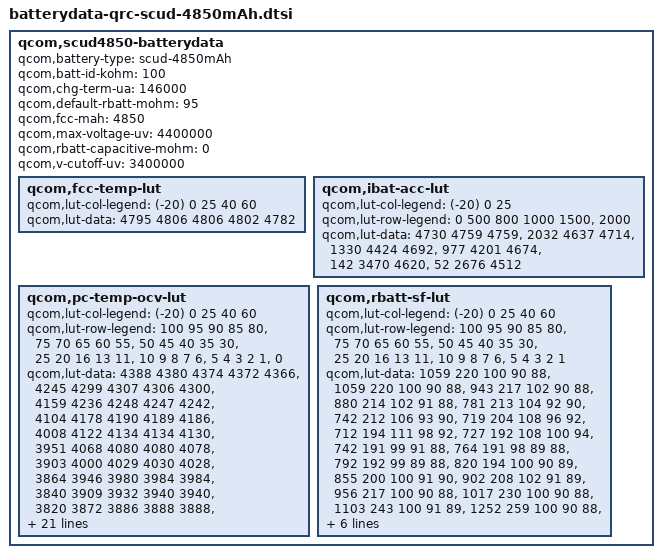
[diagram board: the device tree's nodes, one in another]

qcom,scud4850-batterydata {
	qcom,battery-type = "scud-4850mAh";
	qcom,batt-id-kohm = <100>;
	qcom,chg-term-ua = <146000>;
	qcom,default-rbatt-mohm = <95>;
	qcom,fcc-mah = <4850>;
	qcom,max-voltage-uv = <4400000>;
	qcom,rbatt-capacitive-mohm = <0>;
	qcom,v-cutoff-uv = <3400000>;

	qcom,fcc-temp-lut {
		qcom,lut-col-legend = <(-20) 0 25 40 60>;
		qcom,lut-data = <4795 4806 4806 4802 4782>;
	};

	qcom,ibat-acc-lut {
		qcom,lut-col-legend = <(-20) 0 25>;
		qcom,lut-row-legend = <0 500 800 1000 1500>,
					<2000>;
		qcom,lut-data = <4730 4759 4759>,
				<2032 4637 4714>,
				<1330 4424 4692>,
				<977 4201 4674>,
				<142 3470 4620>,
				<52 2676 4512>;
	};

	qcom,pc-temp-ocv-lut {
		qcom,lut-col-legend = <(-20) 0 25 40 60>;
		qcom,lut-row-legend = <100 95 90 85 80>,
					<75 70 65 60 55>,
					<50 45 40 35 30>,
					<25 20 16 13 11>,
					<10 9 8 7 6>,
					<5 4 3 2 1>,
					<0>;
		qcom,lut-data = <4388 4380 4374 4372 4366>,
				<4245 4299 4307 4306 4300>,
				<4159 4236 4248 4247 4242>,
				<4104 4178 4190 4189 4186>,
				<4008 4122 4134 4134 4130>,
				<3951 4068 4080 4080 4078>,
				<3903 4000 4029 4030 4028>,
				<3864 3946 3980 3984 3984>,
				<3840 3909 3932 3940 3940>,
				<3820 3872 3886 3888 3888>,
				<3802 3842 3852 3854 3853>,
				<3786 3815 3826 3828 3827>,
				<3771 3794 3806 3807 3806>,
				<3756 3778 3788 3788 3788>,
				<3740 3766 3772 3771 3768>,
				<3724 3752 3756 3750 3740>,
				<3704 3736 3738 3731 3718>,
				<3684 3716 3720 3712 3699>,
				<3665 3701 3702 3694 3682>,
				<3650 3692 3691 3685 3672>,
				<3641 3688 3687 3681 3670>,
				<3632 3684 3685 3679 3668>,
				<3620 3680 3683 3677 3666>,
				<3606 3674 3680 3674 3662>,
				<3588 3663 3674 3668 3656>,
				<3566 3646 3661 3654 3640>,
				<3538 3616 3628 3620 3604>,
				<3500 3569 3578 3568 3554>,
				<3448 3503 3508 3499 3486>,
				<3366 3404 3405 3397 3386>,
				<3200 3200 3200 3200 3200>;
	};

	qcom,rbatt-sf-lut {
		qcom,lut-col-legend = <(-20) 0 25 40 60>;
		qcom,lut-row-legend = <100 95 90 85 80>,
					<75 70 65 60 55>,
					<50 45 40 35 30>,
					<25 20 16 13 11>,
					<10 9 8 7 6>,
					<5 4 3 2 1>;
		qcom,lut-data = <1059 220 100 90 88>,
				<1059 220 100 90 88>,
				<943 217 102 90 88>,
				<880 214 102 91 88>,
				<781 213 104 92 90>,
				<742 212 106 93 90>,
				<719 204 108 96 92>,
				<712 194 111 98 92>,
				<727 192 108 100 94>,
				<742 191 99 91 88>,
				<764 191 98 89 88>,
				<792 192 99 89 88>,
				<820 194 100 90 89>,
				<855 200 100 91 90>,
				<902 208 102 91 89>,
				<956 217 100 90 88>,
				<1017 230 100 90 88>,
				<1103 243 100 91 89>,
				<1252 259 100 90 88>,
				<1396 275 100 91 88>,
				<1475 284 100 91 89>,
				<1534 291 101 92 90>,
				<1673 306 104 93 92>,
				<1865 324 106 95 94>,
				<2112 349 109 98 97>,
				<2431 379 109 98 94>,
				<2864 412 106 94 92>,
				<3487 466 106 94 92>,
				<4444 553 110 95 93>,
				<6091 729 114 98 95>;
	};
};
/* TEST_DB_ID=TEST_ID_NOT_SET */
